VERSION ""

NS_ :

BS_:

BU_: Winch Support Boom CraneController

BO_ 2565833600 WinchCommand: 4 CraneController
 SG_ MaxRopeLoad : 16|16@1+ (0.5,0) [0|30000] "kg" Vector__XXX
 SG_ SetRopeSpeed : 0|16@1+ (0.001,-32) [-32|33.535] "m/s" Vector__XXX

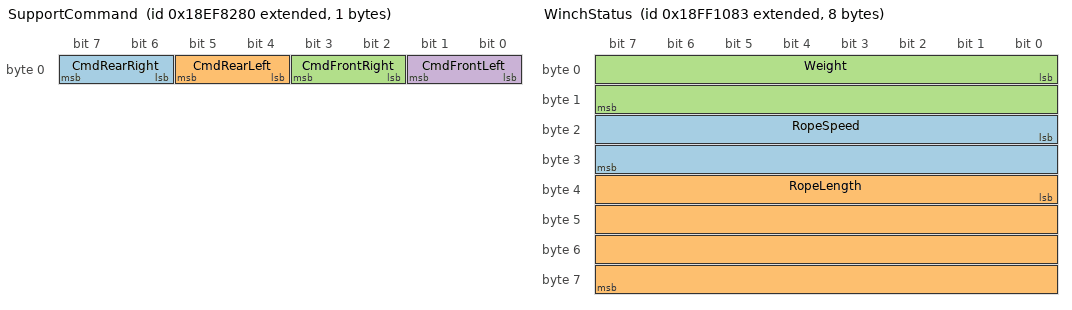
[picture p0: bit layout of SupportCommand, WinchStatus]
BO_ 2565833344 SupportCommand: 1 CraneController
 SG_ CmdRearRight : 6|2@1+ (1,0) [0|3] "" Vector__XXX
 SG_ CmdRearLeft : 4|2@1+ (1,0) [0|3] "" Vector__XXX
 SG_ CmdFrontRight : 2|2@1+ (1,0) [0|3] "" Vector__XXX
 SG_ CmdFrontLeft : 0|2@1+ (1,0) [0|3] "" Vector__XXX

BO_ 2565833088 BoomCommand: 1 CraneController
 SG_ CmdBoom : 2|2@1+ (1,0) [0|3] "%/sec" Vector__XXX
 SG_ CmdAngle : 0|2@1+ (1,0) [0|3] "deg/sec" Vector__XXX

BO_ 2566852739 WinchStatus: 8 Winch
 SG_ RopeSpeed : 16|16@1+ (0.001,-32) [-32|33.535] "m/s" Vector__XXX
 SG_ RopeLength : 32|32@1+ (0.01,0) [0|1000] "m" Vector__XXX
 SG_ Weight : 0|16@1+ (0.5,0) [0|30000] "kg" Vector__XXX

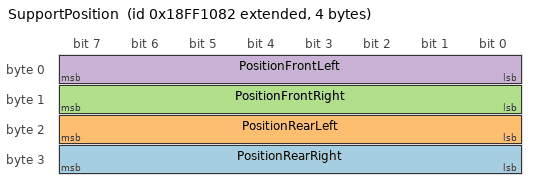
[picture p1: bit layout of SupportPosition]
BO_ 2566852738 SupportPosition: 4 Support
 SG_ PositionRearRight : 24|8@1+ (1,0) [0|100] "%" Vector__XXX
 SG_ PositionRearLeft : 16|8@1+ (1,0) [0|100] "%" Vector__XXX
 SG_ PositionFrontRight : 8|8@1+ (1,0) [0|100] "%" Vector__XXX
 SG_ PositionFrontLeft : 0|8@1+ (1,0) [0|100] "%" Vector__XXX

BO_ 2566852737 BoomPosition: 4 Boom
 SG_ Position : 16|16@1+ (0.1,0) [0|100] "%" Vector__XXX
 SG_ Angle : 0|16@1+ (0.1,0) [0|80] "deg" Vector__XXX

EV_ EvDemoMode: 0 [0|1] "" 1 1 DUMMY_NODE_VECTOR0 Vector__XXX;

EV_ EvCC_HookWeight: 1 [0|30000] "kg" 0 2 DUMMY_NODE_VECTOR0 Vector__XXX;

EV_ EvCC_RopeLength: 1 [0|1000] "m" 0 3 DUMMY_NODE_VECTOR0 Vector__XXX;

EV_ EvBoomLock: 0 [0|1] "" 1 4 DUMMY_NODE_VECTOR0 Vector__XXX;

EV_ EvSupportLock: 0 [0|1] "" 0 5 DUMMY_NODE_VECTOR0 Vector__XXX;

EV_ EvHookBitmap: 0 [0|5] "" 0 6 DUMMY_NODE_VECTOR0 Vector__XXX;

EV_ EvSupportBitmap: 0 [0|4] "" 0 7 DUMMY_NODE_VECTOR0 Vector__XXX;

EV_ EvCraneBitmap: 0 [0|4] "" 0 8 DUMMY_NODE_VECTOR0 Vector__XXX;

EV_ EvCC_BoomAngle: 1 [0|90] "" 0 9 DUMMY_NODE_VECTOR0 Vector__XXX;

EV_ EvBoomDown: 0 [0|1] "" 0 10 DUMMY_NODE_VECTOR0 Vector__XXX;

EV_ EvBoomUp: 0 [0|1] "" 0 11 DUMMY_NODE_VECTOR0 Vector__XXX;

EV_ EvBoomPullIn: 0 [0|1] "" 0 12 DUMMY_NODE_VECTOR0 Vector__XXX;

EV_ EvBoomPullOut: 0 [0|1] "" 0 13 DUMMY_NODE_VECTOR0 Vector__XXX;

EV_ EvWinchDown: 0 [0|1] "" 0 14 DUMMY_NODE_VECTOR0 Vector__XXX;

EV_ EvWinchUp: 0 [0|1] "" 0 15 DUMMY_NODE_VECTOR0 Vector__XXX;

EV_ EvActualWeight: 1 [0|30000] "kg" 500 16 DUMMY_NODE_VECTOR0 Vector__XXX;

EV_ EvSupport_Down: 0 [0|1] "" 0 17 DUMMY_NODE_VECTOR0 Vector__XXX;

EV_ EvSupport_Up: 0 [0|1] "" 0 18 DUMMY_NODE_VECTOR0 Vector__XXX;

EV_ Ev_ECUPower: 0 [0|1] "" 1 19 DUMMY_NODE_VECTOR0 Vector__XXX;

CM_ EV_ EvBoomDown "Decrease angle";
CM_ EV_ EvBoomUp "Increase angle";
CM_ EV_ Ev_ECUPower "Main Power for all ECUs";
BA_DEF_ BO_  "VFrameFormat" ENUM  "StandardCAN","ExtendedCAN","reserved","J1939PG";
BA_DEF_ BO_  "GenMsgSendType" ENUM  "cyclic","reserved","cyclicIfActive","reserved","reserved","reserved","reserved","reserved","noMsgSendType","vector_leerstring";
BA_DEF_ BO_  "GenMsgCycleTime" INT 0 3600000;
BA_DEF_ BO_  "GenMsgRequestable" INT 0 1;
BA_DEF_ BU_  "NmStationAddress" INT 0 255;
BA_DEF_ BU_  "NmJ1939AAC" INT 0 1;
BA_DEF_ BU_  "NmJ1939IndustryGroup" INT 0 7;
BA_DEF_ BU_  "NmJ1939System" INT 0 127;
BA_DEF_ BU_  "NmJ1939SystemInstance" INT 0 15;
BA_DEF_ BU_  "NmJ1939Function" INT 0 255;
BA_DEF_ BU_  "NmJ1939FunctionInstance" INT 0 7;
BA_DEF_ BU_  "NmJ1939ECUInstance" INT 0 7;
BA_DEF_ BU_  "NmJ1939ManufacturerCode" INT 0 2047;
BA_DEF_ BU_  "NmJ1939IdentityNumber" INT 0 2097151;
BA_DEF_ BU_  "ECU" STRING ;
BA_DEF_  "ProtocolType" STRING ;
BA_DEF_ SG_  "SigType" STRING ;
BA_DEF_  "BusType" STRING ;
BA_DEF_DEF_  "VFrameFormat" "J1939PG";
BA_DEF_DEF_  "GenMsgSendType" "noMsgSendType";
BA_DEF_DEF_  "GenMsgCycleTime" 0;
BA_DEF_DEF_  "GenMsgRequestable" 1;
BA_DEF_DEF_  "NmStationAddress" 254;
BA_DEF_DEF_  "NmJ1939AAC" 0;
BA_DEF_DEF_  "NmJ1939IndustryGroup" 0;
BA_DEF_DEF_  "NmJ1939System" 0;
BA_DEF_DEF_  "NmJ1939SystemInstance" 0;
BA_DEF_DEF_  "NmJ1939Function" 0;
BA_DEF_DEF_  "NmJ1939FunctionInstance" 0;
BA_DEF_DEF_  "NmJ1939ECUInstance" 0;
BA_DEF_DEF_  "NmJ1939ManufacturerCode" 0;
BA_DEF_DEF_  "NmJ1939IdentityNumber" 0;
BA_DEF_DEF_  "ECU" "";
BA_DEF_DEF_  "ProtocolType" "";
BA_DEF_DEF_  "SigType" "";
BA_DEF_DEF_  "BusType" "CAN";
BA_ "ProtocolType" "J1939";
BA_ "ECU" BU_ Winch "Winch";
BA_ "NmJ1939IdentityNumber" BU_ Winch 4;
BA_ "NmJ1939ManufacturerCode" BU_ Winch 1861;
BA_ "NmJ1939Function" BU_ Winch 131;
BA_ "NmJ1939System" BU_ Winch 2;
BA_ "NmJ1939IndustryGroup" BU_ Winch 3;
BA_ "NmStationAddress" BU_ Winch 131;
BA_ "ECU" BU_ Support "Support";
BA_ "NmJ1939IdentityNumber" BU_ Support 3;
BA_ "NmJ1939ManufacturerCode" BU_ Support 1861;
BA_ "NmJ1939Function" BU_ Support 130;
BA_ "NmJ1939System" BU_ Support 2;
BA_ "NmJ1939IndustryGroup" BU_ Support 3;
BA_ "NmStationAddress" BU_ Support 130;
BA_ "ECU" BU_ Boom "Jib";
BA_ "NmJ1939IdentityNumber" BU_ Boom 2;
BA_ "NmJ1939ManufacturerCode" BU_ Boom 1861;
BA_ "NmJ1939Function" BU_ Boom 129;
BA_ "NmJ1939System" BU_ Boom 2;
BA_ "NmJ1939IndustryGroup" BU_ Boom 3;
BA_ "NmStationAddress" BU_ Boom 129;
BA_ "ECU" BU_ CraneController "CraneController";
BA_ "NmJ1939IdentityNumber" BU_ CraneController 1;
BA_ "NmJ1939ManufacturerCode" BU_ CraneController 1861;
BA_ "NmJ1939Function" BU_ CraneController 128;
BA_ "NmJ1939System" BU_ CraneController 2;
BA_ "NmJ1939IndustryGroup" BU_ CraneController 3;
BA_ "NmStationAddress" BU_ CraneController 128;
BA_ "GenMsgRequestable" BO_ 2565833600 0;
BA_ "GenMsgCycleTime" BO_ 2565833600 100;
BA_ "GenMsgSendType" BO_ 2565833600 0;
BA_ "GenMsgRequestable" BO_ 2565833344 0;
BA_ "GenMsgCycleTime" BO_ 2565833344 100;
BA_ "GenMsgSendType" BO_ 2565833344 0;
BA_ "GenMsgRequestable" BO_ 2565833088 0;
BA_ "GenMsgCycleTime" BO_ 2565833088 100;
BA_ "GenMsgSendType" BO_ 2565833088 0;
BA_ "GenMsgRequestable" BO_ 2566852739 0;
BA_ "GenMsgCycleTime" BO_ 2566852739 100;
BA_ "GenMsgSendType" BO_ 2566852739 0;
BA_ "GenMsgRequestable" BO_ 2566852738 0;
BA_ "GenMsgCycleTime" BO_ 2566852738 100;
BA_ "GenMsgSendType" BO_ 2566852738 0;
BA_ "GenMsgRequestable" BO_ 2566852737 0;
BA_ "GenMsgCycleTime" BO_ 2566852737 100;
BA_ "GenMsgSendType" BO_ 2566852737 0;
BA_ "SigType" SG_ 2565833600 MaxRopeLoad "RANGE";
BA_ "SigType" SG_ 2565833600 SetRopeSpeed "RANGE";
BA_ "SigType" SG_ 2565833344 CmdRearRight "DISCRETE";
BA_ "SigType" SG_ 2565833344 CmdRearLeft "DISCRETE";
BA_ "SigType" SG_ 2565833344 CmdFrontRight "DISCRETE";
BA_ "SigType" SG_ 2565833344 CmdFrontLeft "DISCRETE";
BA_ "SigType" SG_ 2565833088 CmdBoom "RANGE";
BA_ "SigType" SG_ 2565833088 CmdAngle "RANGE";
BA_ "SigType" SG_ 2566852739 RopeSpeed "RANGE";
BA_ "SigType" SG_ 2566852739 RopeLength "RANGE";
BA_ "SigType" SG_ 2566852739 Weight "RANGE";
BA_ "SigType" SG_ 2566852738 PositionRearRight "RANGE";
BA_ "SigType" SG_ 2566852738 PositionRearLeft "RANGE";
BA_ "SigType" SG_ 2566852738 PositionFrontRight "RANGE";
BA_ "SigType" SG_ 2566852738 PositionFrontLeft "RANGE";
BA_ "SigType" SG_ 2566852737 Position "RANGE";
BA_ "SigType" SG_ 2566852737 Angle "RANGE";
VAL_ 2565833344 CmdRearRight 3 "Reserved" 2 "Down" 1 "Up" 0 "Idle" ;
VAL_ 2565833344 CmdRearLeft 3 "Reserved" 2 "Down" 1 "Up" 0 "Idle" ;
VAL_ 2565833344 CmdFrontRight 3 "Reserved" 2 "Down" 1 "Up" 0 "Idle" ;
VAL_ 2565833344 CmdFrontLeft 3 "Reserved" 2 "Down" 1 "Up" 0 "Idle" ;
VAL_ 2565833088 CmdBoom 3 "Reserved" 2 "PullIn" 1 "PullOut" 0 "Idle" ;
VAL_ 2565833088 CmdAngle 3 "Reserved" 2 "Down" 1 "Up" 0 "Idle" ;
